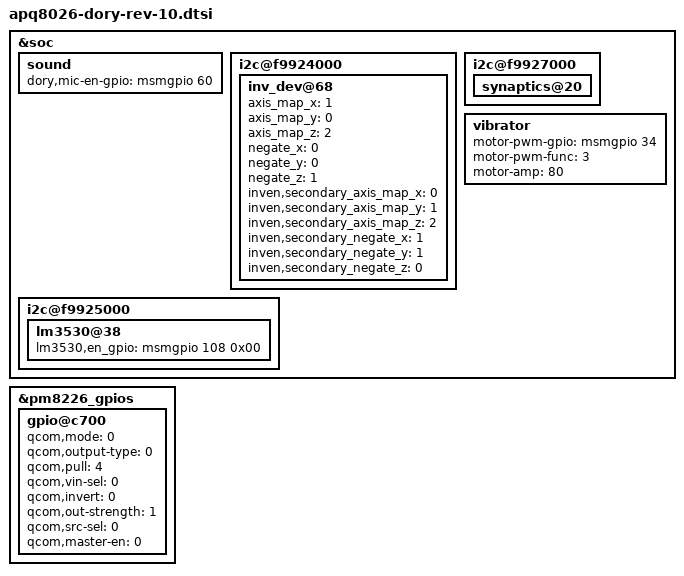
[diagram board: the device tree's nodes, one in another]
/* Copyright (c) 2012, Code Aurora Forum. All rights reserved.
 * Copyright (c) 2013,2014 LGE Inc. All rights reserved.
 *
 * This program is free software; you can redistribute it and/or modify
 * it under the terms of the GNU General Public License version 2 and
 * only version 2 as published by the Free Software Foundation.
 *
 * This program is distributed in the hope that it will be useful,
 * but WITHOUT ANY WARRANTY; without even the implied warranty of
 * MERCHANTABILITY or FITNESS FOR A PARTICULAR PURPOSE.  See the
 * GNU General Public License for more details.
 */

#include "apq8026-dory.dtsi"

&soc {
	sound {
		dory,mic-en-gpio = <&msmgpio 60 0x00>;
	};
	i2c@f9924000 {
		inv_dev@68 {
			axis_map_x = <1>;
			axis_map_y = <0>;
			axis_map_z = <2>;
			negate_x = <0>;
			negate_y = <0>;
			negate_z = <1>;

			inven,secondary_axis_map_x = <0>;
			inven,secondary_axis_map_y = <1>;
			inven,secondary_axis_map_z = <2>;
			inven,secondary_negate_x = <1>;
			inven,secondary_negate_y = <1>;
			inven,secondary_negate_z = <0>;
		};
	};
	i2c@f9925000 {
		lm3530@38 {
			lm3530,en_gpio = <&msmgpio 108 0x00>;
		};
	};
	i2c@f9927000 {
		synaptics@20 {
			status = "ok";
		};
	};
	vibrator {
		motor-pwm-gpio = <&msmgpio 34 0x00>;
		motor-pwm-func = <3>;
		motor-amp = <80>;
	};
};

&pm8226_gpios {
	gpio@c700 { /* GPIO 8 */		/* NOT USED CONFIG */
		qcom,mode = <0>;		/* QPNP_PIN_MODE_DIG_IN */
		qcom,output-type = <0>;		/* QPNP_PIN_OUT_BUF_CMOS */
		qcom,pull = <4>;		/* QPNP_PIN_PULL_DN */
		qcom,vin-sel = <0>;		/* QPNP_PIN_VIN0 */
		qcom,invert = <0>;		/* QPNP_PIN_INVERT_DISABLE */
		qcom,out-strength = <1>;	/* QPNP_PIN_OUT_STRENGTH_LOW */
		qcom,src-sel = <0>;		/* QPNP_PIN_SEL_FUNC_CONSTANT */
		qcom,master-en = <0>;		/* Disable GPIO */
	};
};
